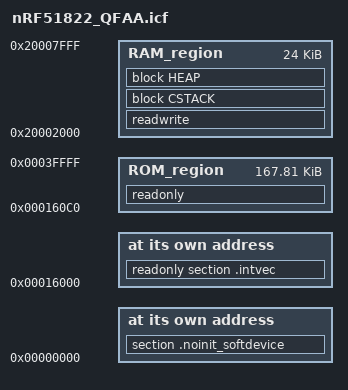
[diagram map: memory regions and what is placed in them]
/*###ICF### Section handled by ICF editor, don't touch! ****/
/*-Editor annotation file-*/
/* IcfEditorFile="$TOOLKIT_DIR$\config\ide\IcfEditor\cortex_v1_0.xml" */
/*-Specials-*/
define symbol __ICFEDIT_intvec_start__ = 0x00016000;
/*-Memory Regions-*/
define symbol __ICFEDIT_region_ROM_start__   = 0x000160c0;
define symbol __ICFEDIT_region_ROM_end__     = 0x0003FFFF;
define symbol __ICFEDIT_region_RAM_start__   = 0x20002000;
define symbol __ICFEDIT_region_RAM_end__     = 0x20007FFF;
/*-Sizes-*/
/*Heap 1/4 of ram and stack 1/8*/
define symbol __ICFEDIT_size_cstack__   = 0xc00;
define symbol __ICFEDIT_size_heap__     = 0x1800;
/**** End of ICF editor section. ###ICF###*/

define symbol __code_start_soft_device__ = 0x0;

define memory mem with size = 4G;
define region ROM_region   = mem:[from __ICFEDIT_region_ROM_start__   to __ICFEDIT_region_ROM_end__];
define region RAM_region   = mem:[from __ICFEDIT_region_RAM_start__   to __ICFEDIT_region_RAM_end__];

define block CSTACK    with alignment = 8, size = __ICFEDIT_size_cstack__   { };
define block HEAP      with alignment = 8, size = __ICFEDIT_size_heap__     { };

initialize by copy { readwrite };
do not initialize  { section .noinit };

keep { section .intvec };
place at address mem:__ICFEDIT_intvec_start__ { readonly section .intvec };
place in ROM_region   { readonly };
place in RAM_region   { readwrite,
                        block CSTACK,
                        block HEAP };
                        
/*This is used for mbed applications build inside the Embedded workbench
Applications build with the python scritps use a hex merge so need to merge it
inside the linker. The linker can only use binary files so the hex merge is not possible
through the linker. That is why a binary is used instead of a hex image for the embedded project.
*/
if(isdefinedsymbol(SOFT_DEVICE_BIN)) 
{
  place at address mem:__code_start_soft_device__ { section .noinit_softdevice };
}
